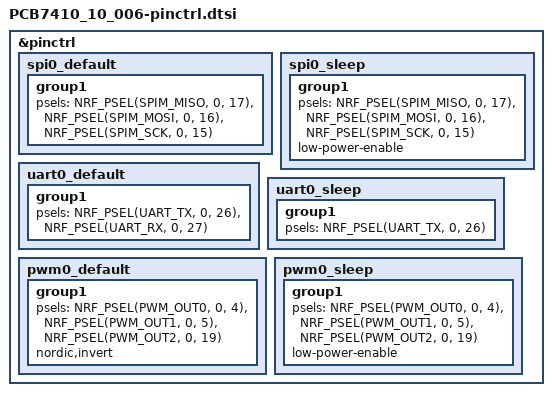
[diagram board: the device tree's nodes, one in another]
&pinctrl {
    spi0_default: spi0_default {
        group1 {
            psels = <NRF_PSEL(SPIM_MISO, 0, 17)>,
                    <NRF_PSEL(SPIM_MOSI, 0, 16)>,
                    <NRF_PSEL(SPIM_SCK, 0, 15)>;
        };
    };

    spi0_sleep: spi0_sleep {
        group1 {
            psels = <NRF_PSEL(SPIM_MISO, 0, 17)>,
                    <NRF_PSEL(SPIM_MOSI, 0, 16)>,
                    <NRF_PSEL(SPIM_SCK, 0, 15)>;
            low-power-enable;
        };
    };

    uart0_default: uart0_default {
        group1 {
            psels = <NRF_PSEL(UART_TX, 0, 26)>, <NRF_PSEL(UART_RX, 0, 27)>;
        };
    };

    uart0_sleep: uart0_sleep {
        group1 {
            psels = <NRF_PSEL(UART_TX, 0, 26)>;
        };
    };

    pwm0_default: pwm0_default {
        group1 {
            psels = <NRF_PSEL(PWM_OUT0, 0, 4)>,
                    <NRF_PSEL(PWM_OUT1, 0, 5)>,
                    <NRF_PSEL(PWM_OUT2, 0, 19)>; 
            nordic,invert;
        };
    };

    pwm0_sleep: pwm0_sleep {
        group1 {
            psels = <NRF_PSEL(PWM_OUT0, 0, 4)>,
                    <NRF_PSEL(PWM_OUT1, 0, 5)>,
                    <NRF_PSEL(PWM_OUT2, 0, 19)>;
            low-power-enable;
        };
    };
};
